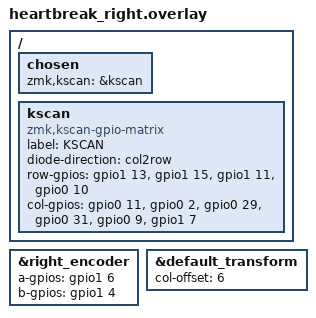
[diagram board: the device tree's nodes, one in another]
// Copyright (c) 2022 The ZMK Contributors
// SPDX-License-Identifier: MIT

#include "heartbreak.dtsi"

/ {
	chosen {
		zmk,kscan = &kscan;
	};

	kscan: kscan {
		compatible = "zmk,kscan-gpio-matrix";

		label = "KSCAN";
		diode-direction = "col2row";
		row-gpios
			= <&gpio1 13 (GPIO_ACTIVE_HIGH | GPIO_PULL_DOWN)>
			, <&gpio1 15 (GPIO_ACTIVE_HIGH | GPIO_PULL_DOWN)>
			, <&gpio1 11 (GPIO_ACTIVE_HIGH | GPIO_PULL_DOWN)>
			, <&gpio0 10 (GPIO_ACTIVE_HIGH | GPIO_PULL_DOWN)>
			;
		col-gpios
			= <&gpio0 11 GPIO_ACTIVE_HIGH>
			, <&gpio0  2 GPIO_ACTIVE_HIGH>
			, <&gpio0 29 GPIO_ACTIVE_HIGH>
			, <&gpio0 31 GPIO_ACTIVE_HIGH>
			, <&gpio0  9 GPIO_ACTIVE_HIGH>
			, <&gpio1  7 GPIO_ACTIVE_HIGH>
			;
	};
};

&right_encoder {
	status = "okay";
	a-gpios = <&gpio1  6 GPIO_PULL_UP>;
	b-gpios = <&gpio1  4 GPIO_PULL_UP>;
};

&default_transform {
	col-offset = <6>;
};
